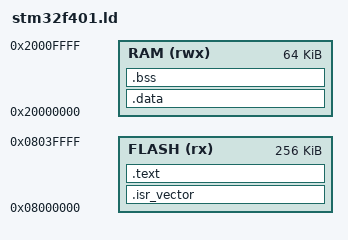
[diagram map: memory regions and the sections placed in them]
MEMORY
{
  FLASH (rx) : ORIGIN = 0x08000000, LENGTH = 256K
  RAM (rwx)  : ORIGIN = 0x20000000, LENGTH = 64K
}

_estack = ORIGIN(RAM) + LENGTH(RAM);

SECTIONS
{
  .isr_vector :
  {
    KEEP(*(.isr_vector))
  } > FLASH

  .text :
  {
    *(.text*)
    *(.rodata*)
    _etext = .;
  } > FLASH

  .data :
  {
    _sidata = LOADADDR(.data);
    _sdata = .;
    *(.data*)
    _edata = .;
  } > RAM

  .bss :
  {
    _sbss = .;
    *(.bss*)
    *(COMMON)
    _ebss = .;
  } > RAM
}
